# STM32F373 register map
File version: 1.7
CPU: CM4 r1p0, little endian, MPU, FPU, 4 interrupt priority bits
Registers are 32-bit, read-write, reset 0x0 unless marked. A register's access mark holds for its fields unless they carry their own. Offsets are from the block's base; [hi:lo] are bit positions; lines under a group give offsets from that group; {n}, {i} and the like mark numbered series; 'fields as' and 'values as' point back to an identical list.

## DMA1 — DMA controller 1
Base 0x40020000
Same registers: DMA2 0x40020400
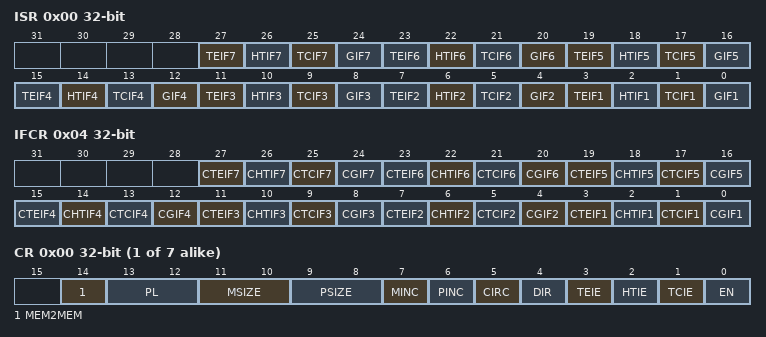
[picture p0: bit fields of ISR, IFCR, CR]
0x00 ISR ro — DMA interrupt status register (DMA_ISR)
  [4n-1] TEIF{n} (n=1..7) — Channel {n} Transfer Error flag
    0=NoError (No transfer error); 1=Error (A transfer error has occured)
  [4n-2] HTIF{n} (n=1..7) — Channel {n} Half Transfer Complete flag
    0=NotHalf (No half transfer event); 1=Half (A half transfer event has occured)
  [4n-3] TCIF{n} (n=1..7) — Channel {n} Transfer Complete flag
    0=NotComplete (No transfer complete event); 1=Complete (A transfer complete event has occured)
  [4n-4] GIF{n} (n=1..7) — Channel {n} Global interrupt flag
    0=NoEvent (No transfer error, half event, complete event); 1=Event (A transfer error, half event or complete event has occured)
0x04 IFCR wo — DMA interrupt flag clear register (DMA_IFCR)
  [4n-1] CTEIF{n} (n=1..7) — Channel {n} Transfer Error clear
    1=Clears the TEIF flag in the ISR register
  [4n-2] CHTIF{n} (n=1..7) — Channel {n} Half Transfer clear
    1=Clears the HTIF flag in the ISR register
  [4n-3] CTCIF{n} (n=1..7) — Channel {n} Transfer Complete clear
    1=Clears the TCIF flag in the ISR register
  [4n-4] CGIF{n} (n=1..7) — Channel {n} Global interrupt clear
    1=Clears the GIF, TEIF, HTIF, TCIF flags in the ISR register
0x08 CH{i} (i=1..7; step 0x14) group — Channel cluster: CCR?, CNDTR?, CPAR?, and CMAR? registers
  0x00 CR — DMA channel configuration register (DMA_CCR)
    [14] MEM2MEM — Memory to memory mode
      0=Disabled (Memory to memory mode disabled); 1=Enabled (Memory to memory mode enabled)
    [13:12] PL — Channel Priority level
      0=Low (Low priority); 1=Medium priority; 2=High priority; 3=Very high priority
    [11:10] MSIZE — Memory size
      0=Bits8 (8-bit size); 1=Bits16 (16-bit size); 2=Bits32 (32-bit size)
    [9:8] PSIZE — Peripheral size
      values as MSIZE
    [7] MINC — Memory increment mode
      0=Disabled (Increment mode disabled); 1=Enabled (Increment mode enabled)
    [6] PINC — Peripheral increment mode
      values as MINC
    [5] CIRC — Circular mode
      0=Disabled (Circular buffer disabled); 1=Enabled (Circular buffer enabled)
    [4] DIR — Data transfer direction
      0=FromPeripheral (Read from peripheral); 1=FromMemory (Read from memory)
    [3] TEIE — Transfer error interrupt enable
      0=Disabled (Transfer Error interrupt disabled); 1=Enabled (Transfer Error interrupt enabled)
    [2] HTIE — Half Transfer interrupt enable
      0=Disabled (Half Transfer interrupt disabled); 1=Enabled (Half Transfer interrupt enabled)
    [1] TCIE — Transfer complete interrupt enable
      0=Disabled (Transfer Complete interrupt disabled); 1=Enabled (Transfer Complete interrupt enabled)
    [0] EN — Channel enable
      0=Disabled (Channel disabled); 1=Enabled (Channel enabled)
  0x04 NDTR — DMA channel 1 number of data register
    [15:0] NDT — Number of data to transfer
  0x08 PAR — DMA channel 1 peripheral address register
    [31:0] PA — Peripheral address
  0x0C MAR — DMA channel 1 memory address register
    [31:0] MA — Memory address

## EXTI — External interrupt/event controller
Base 0x40010400
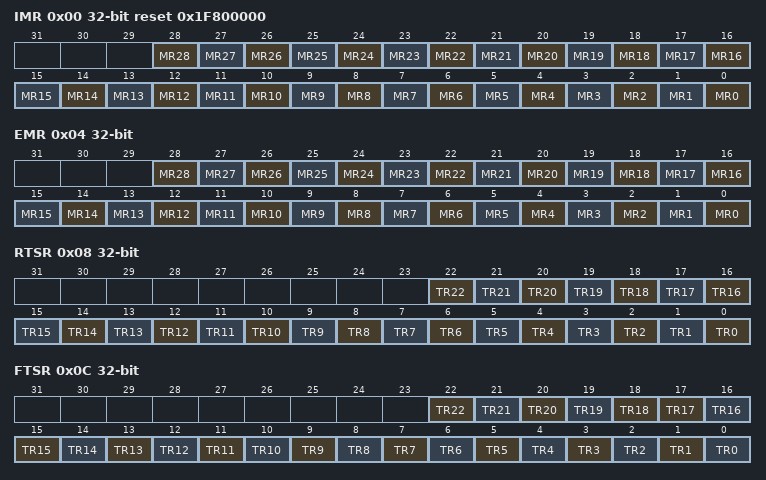
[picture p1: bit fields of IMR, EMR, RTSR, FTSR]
0x00 IMR reset 0x1F800000 — Interrupt mask register (EXTI_IMR)
  [all] fields
    0=Masked (Interrupt request line is masked); 1=Unmasked (Interrupt request line is unmasked)
  [n] MR{n} (n=0..28) — Interrupt Mask on line {n}
0x04 EMR — Event mask register (EXTI_EMR)
  [all] fields
    0=Masked (Event request line is masked); 1=Unmasked (Event request line is unmasked)
  [n] MR{n} (n=0..28) — Event Mask on line {n}
0x08 RTSR — Rising Trigger selection register (EXTI_RTSR)
  [all] fields
    0=Disabled (Rising edge trigger is disabled); 1=Enabled (Rising edge trigger is enabled)
  [n] TR{n} (n=0..22) — Rising trigger event configuration of line {n}
0x0C FTSR — Falling Trigger selection register (EXTI_FTSR)
  [all] fields
    0=Disabled (Falling edge trigger is disabled); 1=Enabled (Falling edge trigger is enabled)
  [n] TR{n} (n=18..22) — Rising trigger event configuration of line {n}
  [n] TR{n} (n=0..17) — Falling trigger event configuration of line {n}
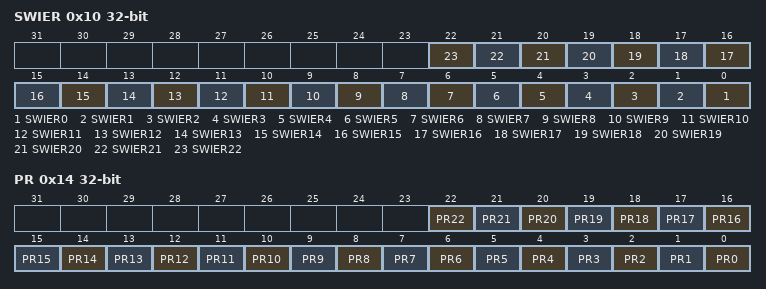
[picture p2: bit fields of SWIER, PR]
0x10 SWIER — Software interrupt event register (EXTI_SWIER)
  [all] fields
    on write: 1=Pend (Generates an interrupt request)
  [n] SWIER{n} (n=0..22) — Software Interrupt on line {n}
0x14 PR — Pending register (EXTI_PR)
  [all] fields
    on read: 0=NotPending (No trigger request occurred); 1=Pending (Selected trigger request occurred) | on write: 1=Clears pending bit
  [n] PR{n} write-1-clears (n=0..22) — Pending bit {n}
